# LPC804 register map
Vendor: nxp.com; File version: 1.0
CPU: CM0PLUS r0p0, little endian, no MPU, no FPU, VTOR, 2 interrupt priority bits
Registers are 32-bit, read-write, reset 0x0 unless marked. A register's access mark holds for its fields unless they carry their own. Offsets are from the block's base; [hi:lo] are bit positions; {n}, {i} and the like mark numbered series.

## SWM0 — LPC804 SWM
Base 0x4000C000
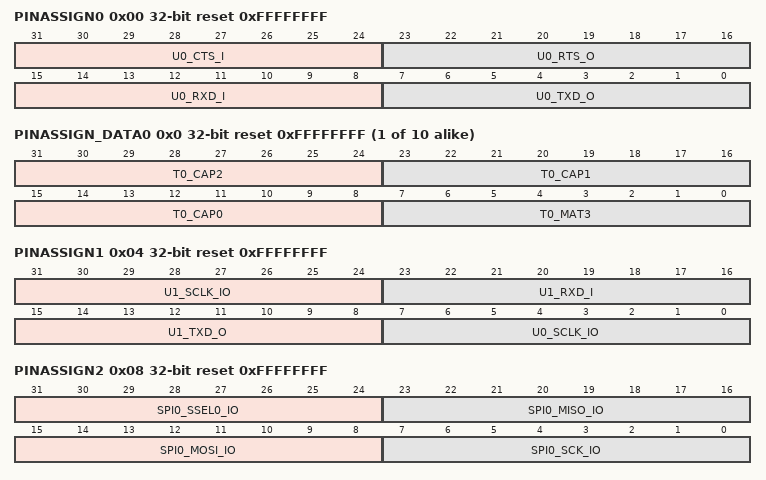
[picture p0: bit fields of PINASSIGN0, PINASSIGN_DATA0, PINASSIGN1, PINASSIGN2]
0x00 PINASSIGN0 reset 0xFFFFFFFF (PINASSIGN_PINASSIGN_DATA view) — Pin assign register 0. Assign movable functions U0_TXD, U0_RXD, U0_RTS, U0_CTS.
  [31:24] U0_CTS_I — U0_CTS function assignment. The value is the pin number to be assigned to this function. The following pins are available: PIO0_0 (= 0) to PIO0_5 (= 0x5) and from PIO0_7 (= 0x7) to PIO0_30 (= 0x1E).
  [23:16] U0_RTS_O — U0_RTS function assignment. The value is the pin number to be assigned to this function. The following pins are available: PIO0_0 (= 0) to PIO0_5 (= 0x5) and from PIO0_7 (= 0x7) to PIO0_30 (= 0x1E).
  [15:8] U0_RXD_I — U0_RXD function assignment. The value is the pin number to be assigned to this function. The following pins are available: PIO0_0 (= 0) to PIO0_5 (= 0x5) and from PIO0_7 (= 0x7) to PIO0_30 (= 0x1E).
  [7:0] U0_TXD_O — U0_TXD function assignment. The value is the pin number to be assigned to this function. The following pins are available: PIO0_0 (= 0) to PIO0_5 (= 0x5) and from PIO0_7 (= 0x7) to PIO0_30 (= 0x1E).
{0x0+4i} PINASSIGN_DATA{i} reset 0xFFFFFFFF (PINASSIGN_PINASSIGN_DATA view) (i=0..9) — Pin assign register
  [31:24] T0_CAP2 — T0_CAP2 function assignment. The value is the pin number to be assigned to this function. The following pins are available: PIO0_0 (= 0) to PIO0_5 (= 0x5) and from PIO0_7 (= 0x7) to PIO0_30 (= 0x1E).
  [23:16] T0_CAP1 — T0_CAP1 function assignment. The value is the pin number to be assigned to this function. The following pins are available: PIO0_0 (= 0) to PIO0_5 (= 0x5) and from PIO0_7 (= 0x7) to PIO0_30 (= 0x1E).
  [15:8] T0_CAP0 — T0_CAP0 function assignment. The value is the pin number to be assigned to this function. The following pins are available: PIO0_0 (= 0) to PIO0_5 (= 0x5) and from PIO0_7 (= 0x7) to PIO0_30 (= 0x1E).
  [7:0] T0_MAT3 — T0_MAT3 function assignment. The value is the pin number to be assigned to this function. The following pins are available: PIO0_0 (= 0) to PIO0_5 (= 0x5) and from PIO0_7 (= 0x7) to PIO0_30 (= 0x1E).
0x04 PINASSIGN1 reset 0xFFFFFFFF (PINASSIGN_PINASSIGN_DATA view) — Pin assign register 1. Assign movable functions U0_SCLK, U1_TXD, U1_RXD, U1_SCLK.
  [31:24] U1_SCLK_IO — U1_SCLK function assignment. The value is the pin number to be assigned to this function. The following pins are available: PIO0_0 (= 0) to PIO0_5 (= 0x5) and from PIO0_7 (= 0x7) to PIO0_30 (= 0x1E).
  [23:16] U1_RXD_I — U1_RXD function assignment. The value is the pin number to be assigned to this function. The following pins are available: PIO0_0 (= 0) to PIO0_5 (= 0x5) and from PIO0_7 (= 0x7) to PIO0_30 (= 0x1E).
  [15:8] U1_TXD_O — U1_TXD function assignment. The value is the pin number to be assigned to this function. The following pins are available: PIO0_0 (= 0) to PIO0_5 (= 0x5) and from PIO0_7 (= 0x7) to PIO0_30 (= 0x1E).
  [7:0] U0_SCLK_IO — U0_SCLK function assignment. The value is the pin number to be assigned to this function. The following pins are available: PIO0_0 (= 0) to PIO0_5 (= 0x5) and from PIO0_7 (= 0x7) to PIO0_30 (= 0x1E).
0x08 PINASSIGN2 reset 0xFFFFFFFF (PINASSIGN_PINASSIGN_DATA view) — Pin assign register 2. Assign movable functions SPI0_SCK, SPI0_MOSI,SPI0_MISO,SPI0_SSEL0.
  [31:24] SPI0_SSEL0_IO — SPI0_SSEL0 function assignment. The value is the pin number to be assigned to this function. The following pins are available: PIO0_0 (= 0) to PIO0_5 (= 0x5) and from PIO0_7 (= 0x7) to PIO0_30 (= 0x1E).
  [23:16] SPI0_MISO_IO — SPI0_MISO function assignment. The value is the pin number to be assigned to this function. The following pins are available: PIO0_0 (= 0) to PIO0_5 (= 0x5) and from PIO0_7 (= 0x7) to PIO0_30 (= 0x1E).
  [15:8] SPI0_MOSI_IO — SPI0_MOSI function assignment. The value is the pin number to be assigned to this function. The following pins are available: PIO0_0 (= 0) to PIO0_5 (= 0x5) and from PIO0_7 (= 0x7) to PIO0_30 (= 0x1E).
  [7:0] SPI0_SCK_IO — SPI0_SCK function assignment. The value is the pin number to be assigned to this function. The following pins are available: PIO0_0 (= 0) to PIO0_5 (= 0x5) and from PIO0_7 (= 0x7) to PIO0_30 (= 0x1E).
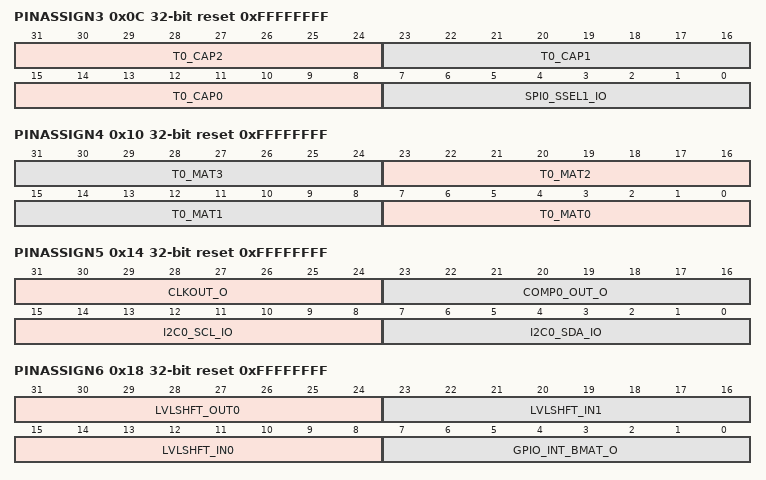
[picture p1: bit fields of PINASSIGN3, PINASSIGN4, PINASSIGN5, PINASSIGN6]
0x0C PINASSIGN3 reset 0xFFFFFFFF (PINASSIGN_PINASSIGN_DATA view) — Pin assign register 3. Assign movable function SPI0_SSEL1, T0_CAP0, T0_CAP1, T0_CAP2.
  [31:24] T0_CAP2 — T0_CAP2 function assignment. The value is the pin number to be assigned to this function. The following pins are available: PIO0_0 (= 0) to PIO0_5 (= 0x5) and from PIO0_7 (= 0x7) to PIO0_30 (= 0x1E).
  [23:16] T0_CAP1 — T0_CAP1 function assignment. The value is the pin number to be assigned to this function. The following pins are available: PIO0_0 (= 0) to PIO0_5 (= 0x5) and from PIO0_7 (= 0x7) to PIO0_30 (= 0x1E).
  [15:8] T0_CAP0 — T0_CAP0 function assignment. The value is the pin number to be assigned to this function. The following pins are available: PIO0_0 (= 0) to PIO0_5 (= 0x5) and from PIO0_7 (= 0x7) to PIO0_30 (= 0x1E).
  [7:0] SPI0_SSEL1_IO — SPI0_SSEL1 function assignment. The value is the pin number to be assigned to this function. The following pins are available: PIO0_0 (= 0) to PIO0_5 (= 0x5) and from PIO0_7 (= 0x7) to PIO0_30 (= 0x1E).
0x10 PINASSIGN4 reset 0xFFFFFFFF (PINASSIGN_PINASSIGN_DATA view) — Pin assign register 4. Assign movable functions T0_MAT0, T0_MAT1,T0_MAT2,T0_MAT3.
  [8n+7:8n] T0_MAT{n} (n=0..3) — T0_MAT{n} function assignment. The value is the pin number to be assigned to this function. The following pins are available: PIO0_0 (= 0) to PIO0_5 (= 0x5) and from PIO0_7 (= 0x7) to PIO0_30 (= 0x1E).
0x14 PINASSIGN5 reset 0xFFFFFFFF (PINASSIGN_PINASSIGN_DATA view) — Pin assign register 5. Assign movable functions I2C0_SDA, I2C0_SCL, COMP0_OUT, CLKOUT
  [31:24] CLKOUT_O — CLKOUT function assignment. The value is the pin number to be assigned to this function. The following pins are available: PIO0_0 (= 0) to PIO0_5 (= 0x5) and from PIO0_7 (= 0x7) to PIO0_30 (= 0x1E).
  [23:16] COMP0_OUT_O — COMP0_OUT function assignment. The value is the pin number to be assigned to this function. The following pins are available: PIO0_0 (= 0) to PIO0_5 (= 0x5) and from PIO0_7 (= 0x7) to PIO0_30 (= 0x1E).
  [15:8] I2C0_SCL_IO — I2C0_SCL function assignment. The value is the pin number to be assigned to this function. The following pins are available: PIO0_0 (= 0) to PIO0_5 (= 0x5) and from PIO0_7 (= 0x7) to PIO0_30 (= 0x1E).
  [7:0] I2C0_SDA_IO — I2C0_SDA function assignment. The value is the pin number to be assigned to this function. The following pins are available: PIO0_0 (= 0) to PIO0_5 (= 0x5) and from PIO0_7 (= 0x7) to PIO0_30 (= 0x1E).
0x18 PINASSIGN6 reset 0xFFFFFFFF (PINASSIGN_PINASSIGN_DATA view) — Pin assign register 6. Assign movable functions GPIO_INT_BMAT, LVLSHFT_IN0, LVLSHFT_IN1, LVLSHFT_OUT0.
  [31:24] LVLSHFT_OUT0 — LVLSHFT_OUT0 function assignment. The value is the pin number to be assigned to this function. The following pins are available: PIO0_0 (= 0) to PIO0_5 (= 0x5) and from PIO0_7 (= 0x7) to PIO0_30 (= 0x1E).
  [23:16] LVLSHFT_IN1 — LVLSHFT_IN1 function assignment. The value is the pin number to be assigned to this function. The following pins are available: PIO0_0 (= 0) to PIO0_5 (= 0x5) and from PIO0_7 (= 0x7) to PIO0_30 (= 0x1E).
  [15:8] LVLSHFT_IN0 — LVLSHFT_IN0 function assignment. The value is the pin number to be assigned to this function. The following pins are available: PIO0_0 (= 0) to PIO0_5 (= 0x5) and from PIO0_7 (= 0x7) to PIO0_30 (= 0x1E).
  [7:0] GPIO_INT_BMAT_O — GPIO_INT_BMAT function assignment. The value is the pin number to be assigned to this function. The following pins are available: PIO0_0 (= 0) to PIO0_5 (= 0x5) and from PIO0_7 (= 0x7) to PIO0_30 (= 0x1E).
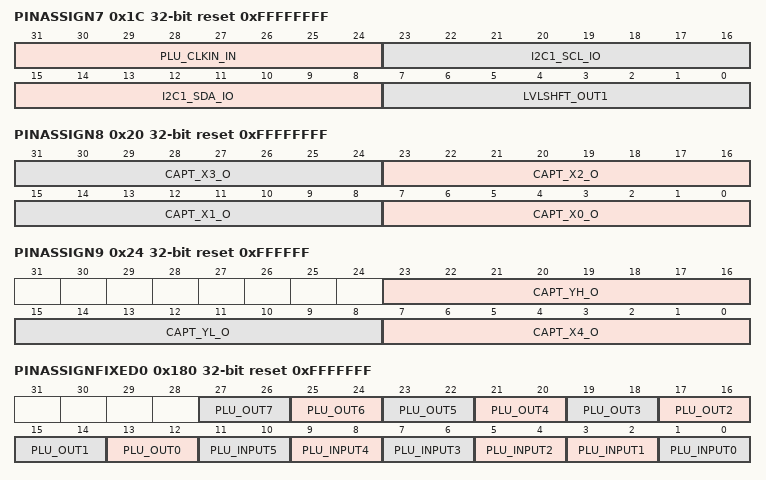
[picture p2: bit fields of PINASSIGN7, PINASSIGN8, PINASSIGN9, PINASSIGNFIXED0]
0x1C PINASSIGN7 reset 0xFFFFFFFF (PINASSIGN_PINASSIGN_DATA view) — Pin assign register 7. Assign movable functions LVLSHFT_OUT1, I2C1_SDA, I2C1_SCL, PLU_CLKIN.
  [31:24] PLU_CLKIN_IN — PLU_CLKIN function assignment. The value is the pin number to be assigned to this function. The following pins are available: PIO0_0 (= 0) to PIO0_5 (= 0x5) and from PIO0_7 (= 0x7) to PIO0_30 (= 0x1E).
  [23:16] I2C1_SCL_IO — I2C1_SCL function assignment. The value is the pin number to be assigned to this function. The following pins are available: PIO0_0 (= 0) to PIO0_5 (= 0x5) and from PIO0_7 (= 0x7) to PIO0_30 (= 0x1E).
  [15:8] I2C1_SDA_IO — I2C1_SDA function assignment. The value is the pin number to be assigned to this function. The following pins are available: PIO0_0 (= 0) to PIO0_5 (= 0x5) and from PIO0_7 (= 0x7) to PIO0_30 (= 0x1E).
  [7:0] LVLSHFT_OUT1 — LVLSHFT_OUT1 function assignment. The value is the pin number to be assigned to this function. The following pins are available: PIO0_0 (= 0) to PIO0_5 (= 0x5) and from PIO0_7 (= 0x7) to PIO0_30 (= 0x1E).
0x20 PINASSIGN8 reset 0xFFFFFFFF (PINASSIGN_PINASSIGN_DATA view) — Pin assign register 8. Assign movable functions CAPT_X0, CAPT_X1, CAPT_X2, CAPT_X3.
  [8n+7:8n] CAPT_X{n}_O (n=0..3) — CAPT_X{n} function assignment. The value is the pin number to be assigned to this function. The following pins are available: PIO0_0 (= 0) to PIO0_5 (= 0x5) and from PIO0_7 (= 0x7) to PIO0_30 (= 0x1E).
0x24 PINASSIGN9 reset 0xFFFFFF (PINASSIGN_PINASSIGN_DATA view) — Pin assign register 9. Assign movable functions CAPT_X4, CAPT_YL, CAPT_YH.
  [23:16] CAPT_YH_O — CAPT_YH_O function assignment. The value is the pin number to be assigned to this function. The following pins are available: PIO0_0 (= 0) to PIO0_5 (= 0x5) and from PIO0_7 (= 0x7) to PIO0_30 (= 0x1E).
  [15:8] CAPT_YL_O — CAPT_YL function assignment. The value is the pin number to be assigned to this function. The following pins are available: PIO0_0 (= 0) to PIO0_5 (= 0x5) and from PIO0_7 (= 0x7) to PIO0_30 (= 0x1E).
  [7:0] CAPT_X4_O — CAPT_X4 function assignment. The value is the pin number to be assigned to this function. The following pins are available: PIO0_0 (= 0) to PIO0_5 (= 0x5) and from PIO0_7 (= 0x7) to PIO0_30 (= 0x1E).
0x180 PINASSIGNFIXED0 reset 0xFFFFFFF — Pin assign to fixed bits register 0. Pin assign to fixed bits register 0. Assign movable functions PLU_INPUT0 to PLU_INPUT5 and PLU_OUT0 to PLU_INPUT7.
  [2n+13:2n+12] PLU_OUT{n} (n=0..7) — PLU_OUT{n} function assignment.
    0=Assign_PIO0_{n+7:02} (Assign to PIO0_{n+7:02}.); 1=Assign_PIO0_{n+14} (Assign to PIO0_{n+14}.); 2=Assign_PIO0_{n+23} (Assign to PIO0_{n+23}.); 3=None
  [2n+1:2n] PLU_INPUT{n} (n=2..5) — PLU_INPUT{n} function assignment.
    0=Assign_PIO0_{n:02} (Assign to PIO0_{n:02}.); 1=Assign_PIO0_{n+8} (Assign to PIO0_{n+8}.); 2=Assign_PIO0_{n+17} (Assign to PIO0_{n+17}.); 3=None
  [3:2] PLU_INPUT1 — PLU_INPUT1 function assignment
    0=Assign_PIO0_01 (Assign to PIO0_01.); 1=Assign_PIO0_09 (Assign to PIO0_09.); 2=Assign_PIO0_18 (Assign to PIO0_18.); 3=None
  [1:0] PLU_INPUT0 — PLU_INPUT0 function assignment.
    0=Assign_PIO0_00 (Assign to PIO0_00.); 1=Assign_PIO0_08 (Assign to PIO0_08.); 2=Assign_PIO0_17 (Assign to PIO0_17.); 3=None
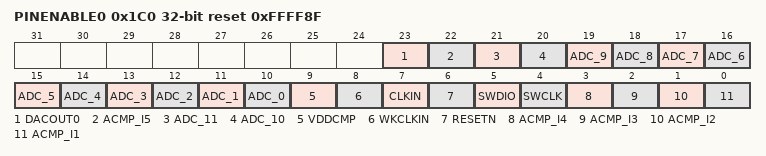
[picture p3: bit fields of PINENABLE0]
0x1C0 PINENABLE0 reset 0xFFFF8F — Pin enable register 0. Enables fixed-pin functions ACMP_I1, ACMP_I2, ACMP_I3,ACMP_I4, SWCLK, SWDIO, RESETN, CLKIN,WKCLK_IN, VDDCMP, ADC_0 - ADC_11,ACMP_I5,DACOUT0.
  [23] DACOUT0 — DACOUT0 function select.
    0=ENABLED (DACOUT0 enabled on pin PIO0_19.); 1=DISABLED (DACOUT0 disabled.)
  [22] ACMP_I5 — ACMP_I5 function select.
    0=ENABLED (ACMP_I5 enabled on pin PIO0_21.); 1=DISABLED (ACMP_I5 disabled.)
  [21] ADC_11 — ADC_11 function select.
    0=ENABLED (ADC_11 enabled on pin PIO0_4.); 1=DISABLED (ADC_11 disabled.)
  [20] ADC_10 — ADC_10 function select.
    0=ENABLED (ADC_10 enabled on pin PIO0_13.); 1=DISABLED (ADC_10 disabled.)
  [19] ADC_9 — ADC_9 function select.
    0=ENABLED (ADC_9 enabled on pin PIO0_17.); 1=DISABLED (ADC_9 disabled.)
  [18] ADC_8 — ADC_8 function select.
    0=ENABLED (ADC_8 enabled on pin PIO0_15.); 1=DISABLED (ADC_8 disabled.)
  [17] ADC_7 — ADC_7 function select.
    0=ENABLED (ADC_7 enabled on pin PIO0_10.); 1=DISABLED (ADC_7 disabled.)
  [16] ADC_6 — ADC_6 function select.
    0=ENABLED (ADC_6 enabled on pin PIO0_11.); 1=DISABLED (ADC_6 disabled.)
  [15] ADC_5 — ADC_5 function select.
    0=ENABLED (ADC_5 enabled on pin PIO0_8.); 1=DISABLED (ADC_5 disabled.)
  [14] ADC_4 — ADC_4 function select.
    0=ENABLED (ADC_4 enabled on pin PIO0_9.); 1=DISABLED (ADC_4 disabled.)
  [13] ADC_3 — ADC_3 function select.
    0=ENABLED (ADC_3 enabled on pin PIO0_16.); 1=DISABLED (ADC_3 disabled.)
  [12] ADC_2 — ADC_2 function select.
    0=ENABLED (ADC_2 enabled on pin PIO0_14.); 1=DISABLED (ADC_2 disabled.)
  [11] ADC_1 — ADC_1 function select.
    0=ENABLED (ADC_1 enabled on pin PIO0_7.); 1=DISABLED (ADC_1 disabled.)
  [10] ADC_0 — ADC_0 function select.
    0=ENABLED (ADC_0 enabled on pin PIO0_1.); 1=DISABLED (ADC_0 disabled.)
  [9] VDDCMP — VDDCMP function select.
    0=ENABLED (VDDCMP enabled on pin PIO0_6.); 1=DISABLED (VDDCMP disabled.)
  [8] WKCLKIN — WKCLK_IN function select.
    0=ENABLED (WKCLK_IN enabled on pin PIO0_11.); 1=DISABLED (WKCLK_IN disabled.)
  [7] CLKIN — CLKIN function select.
    0=ENABLED (CLKIN enabled on pin PIO0_1.); 1=DISABLED (CLKIN disabled.)
  [6] RESETN — RESETN function select.
    0=ENABLED (RESETN enabled on pin PIO0_5.); 1=DISABLED (RESETN disabled.)
  [5] SWDIO — SWDIO function select.
    0=ENABLED (SWDIO enabled on pin PIO0_2.); 1=DISABLED (SWDIO disabled.)
  [4] SWCLK — SWCLK function select.
    0=ENABLED (SWCLK enabled on pin PIO0_3.); 1=DISABLED (SWCLK disabled.)
  [3] ACMP_I4 — ACMP_I4 function select.
    0=ENABLED (ACMP_I4 enabled on pin PIO0_16.); 1=DISABLED (ACMP_I4 disabled.)
  [2] ACMP_I3 — ACMP_I3 function select.
    0=ENABLED (ACMP_I3 enabled on pin PIO0_14.); 1=DISABLED (ACMP_I3 disabled.)
  [1] ACMP_I2 — ACMP_I2 function select.
    0=ACMP_I2 enabled on pin PIO0_1; 1=ACMP_I2 disabled
  [0] ACMP_I1 — ACMP_I1 function select.
    0=ENABLED (ACMP_I1 enabled on pin PIO0_00.); 1=DISABLED (ACMP_I1 disabled.)

## Notices in the file
Copyright 2016-2019 NXP
All rights reserved.
SPDX-License-Identifier: BSD-3-Clause
